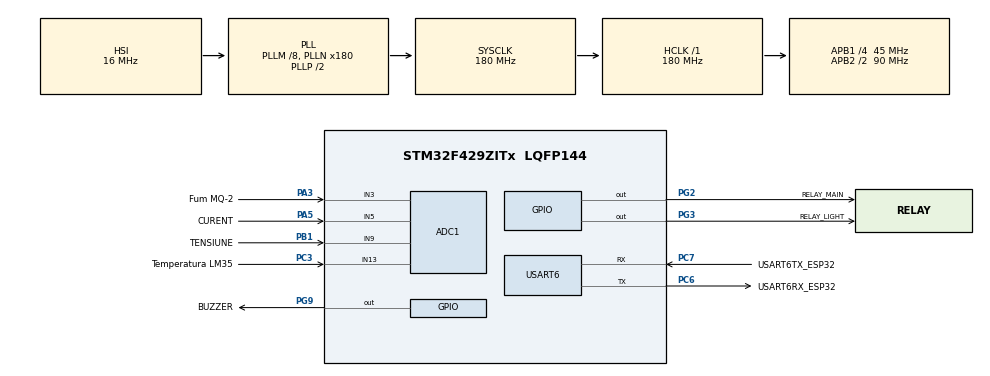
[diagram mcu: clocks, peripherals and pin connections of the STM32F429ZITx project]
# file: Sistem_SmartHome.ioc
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ADC1.Channel-0\#ChannelRegularConversion=ADC_CHANNEL_9
ADC1.Channel-1\#ChannelRegularConversion=ADC_CHANNEL_5
ADC1.Channel-2\#ChannelRegularConversion=ADC_CHANNEL_3
ADC1.Channel-3\#ChannelRegularConversion=ADC_CHANNEL_13
ADC1.ContinuousConvMode=ENABLE
ADC1.DMAContinuousRequests=ENABLE
ADC1.DiscontinuousConvMode=DISABLE
ADC1.NbrOfConversion=4
ADC1.NbrOfConversionFlag=1
ADC1.Rank-0\#ChannelRegularConversion=1
ADC1.Rank-1\#ChannelRegularConversion=2
ADC1.Rank-2\#ChannelRegularConversion=3
ADC1.Rank-3\#ChannelRegularConversion=4
ADC1.SamplingTime-0\#ChannelRegularConversion=ADC_SAMPLETIME_84CYCLES
ADC1.SamplingTime-1\#ChannelRegularConversion=ADC_SAMPLETIME_84CYCLES
ADC1.SamplingTime-2\#ChannelRegularConversion=ADC_SAMPLETIME_84CYCLES
ADC1.SamplingTime-3\#ChannelRegularConversion=ADC_SAMPLETIME_84CYCLES
ADC1.ScanConvMode=ENABLE
ADC1.master=1
Dma.ADC1.0.Direction=DMA_PERIPH_TO_MEMORY
Dma.ADC1.0.FIFOMode=DMA_FIFOMODE_DISABLE
Dma.ADC1.0.Instance=DMA2_Stream0
Dma.ADC1.0.MemDataAlignment=DMA_MDATAALIGN_HALFWORD
Dma.ADC1.0.MemInc=DMA_MINC_ENABLE
Dma.ADC1.0.Mode=DMA_CIRCULAR
Dma.ADC1.0.PeriphDataAlignment=DMA_PDATAALIGN_HALFWORD
Dma.ADC1.0.PeriphInc=DMA_PINC_DISABLE
Dma.ADC1.0.Priority=DMA_PRIORITY_LOW
Dma.Request0=ADC1
Mcu.Family=STM32F4
Mcu.Name=STM32F429ZITx
Mcu.Package=LQFP144
NVIC.DMA2_Stream0_IRQn=true\:0\:0\:false\:false\:true\:false\:true\:true
NVIC.PriorityGroup=NVIC_PRIORITYGROUP_4
NVIC.USART6_IRQn=true\:0\:0\:false\:false\:true\:true\:true\:true
PA13.Mode=Serial_Wire
PA13.Signal=SYS_JTMS-SWDIO
PA14.Mode=Serial_Wire
PA14.Signal=SYS_JTCK-SWCLK
PA3.GPIO_Label=Fum MQ-2
PA3.Signal=ADCx_IN3
PA5.GPIO_Label=CURENT
PA5.Signal=ADCx_IN5
PB1.GPIO_Label=TENSIUNE
PB1.Signal=ADCx_IN9
PC3.GPIO_Label=Temperatura LM35
PC3.Signal=ADCx_IN13
PC6.GPIO_Label=USART6RX_ESP32
PC6.Mode=Asynchronous
PC6.Signal=USART6_TX
PC7.GPIO_Label=USART6TX_ESP32
PC7.Mode=Asynchronous
PC7.Signal=USART6_RX
PG2.GPIO_Label=RELAY_MAIN
PG2.PinState=GPIO_PIN_SET
PG2.Signal=GPIO_Output
PG3.GPIO_Label=RELAY_LIGHT
PG3.PinState=GPIO_PIN_SET
PG3.Signal=GPIO_Output
PG9.GPIO_Label=BUZZER
PG9.PinState=GPIO_PIN_RESET
PG9.Signal=GPIO_Output
PH0/OSC_IN.Mode=HSE-External-Oscillator
PH0/OSC_IN.Signal=RCC_OSC_IN
PH1/OSC_OUT.Mode=HSE-External-Oscillator
PH1/OSC_OUT.Signal=RCC_OSC_OUT
ProjectManager.HeapSize=0x200
ProjectManager.StackSize=0x400
ProjectManager.TargetToolchain=STM32CubeIDE
RCC.48MHZClocksFreq_Value=90000000
RCC.AHBFreq_Value=180000000
RCC.APB1CLKDivider=RCC_HCLK_DIV4
RCC.APB1Freq_Value=45000000
RCC.APB1TimFreq_Value=90000000
RCC.APB2CLKDivider=RCC_HCLK_DIV2
RCC.APB2Freq_Value=90000000
RCC.APB2TimFreq_Value=180000000
RCC.CortexFreq_Value=180000000
RCC.HCLKFreq_Value=180000000
RCC.HSE_VALUE=25000000
RCC.HSI_VALUE=16000000
RCC.LSE_VALUE=32768
RCC.PLLM=8
RCC.PLLN=180
RCC.SYSCLKFreq_VALUE=180000000
RCC.SYSCLKSource=RCC_SYSCLKSOURCE_PLLCLK
RCC.VCOOutputFreq_Value=360000000
SH.ADCx_IN13.0=ADC1_IN13,IN13
SH.ADCx_IN3.0=ADC1_IN3,IN3
SH.ADCx_IN5.0=ADC1_IN5,IN5
SH.ADCx_IN9.0=ADC1_IN9,IN9
USART6.VirtualMode=VM_ASYNC
board=custom

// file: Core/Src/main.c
/* USER CODE BEGIN Header */
/**
  ******************************************************************************
  * @file           : main.c
  * @brief          : Main program body
  ******************************************************************************
  * @attention
  *
  * Copyright (c) 2026 STMicroelectronics.
  * All rights reserved.
  *
  * This software is licensed under terms that can be found in the LICENSE file
  * in the root directory of this software component.
  * If no LICENSE file comes with this software, it is provided AS-IS.
  *
  ******************************************************************************
  */
/* USER CODE END Header */
#include "main.h"
#include "adc.h"
#include "dma.h"
#include "usart.h"
#include "gpio.h"

/* USER CODE BEGIN Includes */
#include "app_safety.h"

/* USER CODE END Includes */

void SystemClock_Config(void);

int main(void)
{

  /* MCU Configuration--------------------------------------------------------*/

  /* Reset of all peripherals, Initializes the Flash interface and the Systick. */
  HAL_Init();

  /* Configure the system clock */
  SystemClock_Config();

  /* Initialize all configured peripherals */
  MX_GPIO_Init();
  MX_DMA_Init();
  MX_ADC1_Init();
  MX_USART6_UART_Init();
  /* USER CODE BEGIN 2 */
  App_Safety_Init();   /* calibrare ACS712, pornire ADC+DMA, receptie UART */

  /* USER CODE END 2 */

  /* Infinite loop */
  while (1)
  {

    /* USER CODE BEGIN 3 */
    App_Safety_Process(); /* non-blocant: senzori, protectii, protocol UART */
  }
  /* USER CODE END 3 */
}

void SystemClock_Config(void)
{
  RCC_OscInitTypeDef RCC_OscInitStruct = {0};
  RCC_ClkInitTypeDef RCC_ClkInitStruct = {0};

  /** Configure the main internal regulator output voltage
  */
  __HAL_RCC_PWR_CLK_ENABLE();
  __HAL_PWR_VOLTAGESCALING_CONFIG(PWR_REGULATOR_VOLTAGE_SCALE1);

  /** Initializes the RCC Oscillators according to the specified parameters
  * in the RCC_OscInitTypeDef structure.
  */
  RCC_OscInitStruct.OscillatorType = RCC_OSCILLATORTYPE_HSI;
  RCC_OscInitStruct.HSIState = RCC_HSI_ON;
  RCC_OscInitStruct.HSICalibrationValue = RCC_HSICALIBRATION_DEFAULT;
  RCC_OscInitStruct.PLL.PLLState = RCC_PLL_ON;
  RCC_OscInitStruct.PLL.PLLSource = RCC_PLLSOURCE_HSI;
  RCC_OscInitStruct.PLL.PLLM = 8;
  RCC_OscInitStruct.PLL.PLLN = 180;
  RCC_OscInitStruct.PLL.PLLP = RCC_PLLP_DIV2;
  RCC_OscInitStruct.PLL.PLLQ = 4;
  if (HAL_RCC_OscConfig(&RCC_OscInitStruct) != HAL_OK)
  {
    Error_Handler();
  }

  /** Activate the Over-Drive mode
  */
  if (HAL_PWREx_EnableOverDrive() != HAL_OK)
  {
    Error_Handler();
  }

  /** Initializes the CPU, AHB and APB buses clocks
  */
  RCC_ClkInitStruct.ClockType = RCC_CLOCKTYPE_HCLK|RCC_CLOCKTYPE_SYSCLK
                              |RCC_CLOCKTYPE_PCLK1|RCC_CLOCKTYPE_PCLK2;
  RCC_ClkInitStruct.SYSCLKSource = RCC_SYSCLKSOURCE_PLLCLK;
  RCC_ClkInitStruct.AHBCLKDivider = RCC_SYSCLK_DIV1;
  RCC_ClkInitStruct.APB1CLKDivider = RCC_HCLK_DIV4;
  RCC_ClkInitStruct.APB2CLKDivider = RCC_HCLK_DIV2;

  if (HAL_RCC_ClockConfig(&RCC_ClkInitStruct, FLASH_LATENCY_5) != HAL_OK)
  {
    Error_Handler();
  }
}

void Error_Handler(void)
{
  __disable_irq();
  while (1)
  {
  }
}
